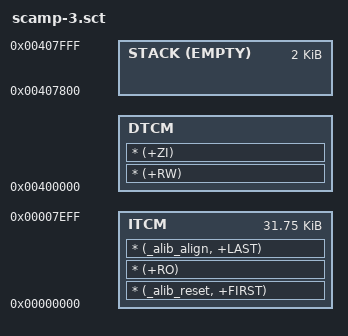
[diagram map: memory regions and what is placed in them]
#
# Scatter load file for SC&MP in RAM
#

IMAGE 0
{
        ITCM 0 0x7f00
        {
                * (_alib_reset, +FIRST)
                * (+RO)
                * (_alib_align, +LAST)
        }

        DTCM 0x00400000
        {
                * (+RW)
                * (+ZI)
        }

        STACK 0x00408000 EMPTY -0x800
        {
        }
}
